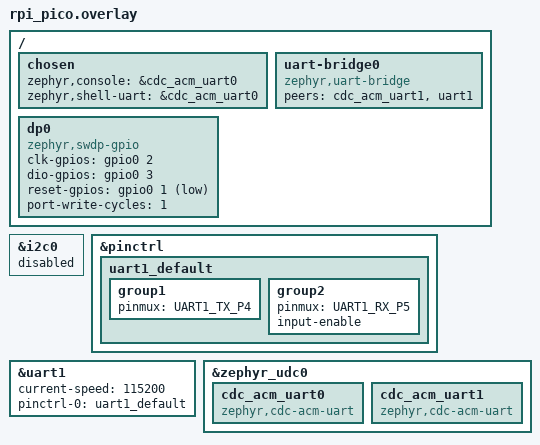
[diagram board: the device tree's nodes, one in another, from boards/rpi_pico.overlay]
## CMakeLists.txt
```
# SPDX-License-Identifier: Apache-2.0

cmake_minimum_required(VERSION 3.20.0)
find_package(Zephyr REQUIRED HINTS $ENV{ZEPHYR_BASE})
project(pico_probe)

FILE(GLOB app_sources src/*.c)
target_sources(app PRIVATE ${app_sources})
```

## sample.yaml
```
sample:
  name: Pico Probe CMSIS-DAP

tests:
  app.default:
    build_only: true
```

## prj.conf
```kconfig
# Enable USB device susbsytem
CONFIG_USB_DEVICE_STACK_NEXT=y

# CMSIS-DAP
CONFIG_DAP=y
CONFIG_DAP_BACKEND_USB=y

# Serial
CONFIG_SERIAL=y
CONFIG_UART_INTERRUPT_DRIVEN=y
CONFIG_UART_LINE_CTRL=y

# GPIO
CONFIG_GPIO=y

# Logs
CONFIG_LOG=y

# Don't auto-init CDC-ACM (we do it manually)
CONFIG_CDC_ACM_SERIAL_INITIALIZE_AT_BOOT=n
```

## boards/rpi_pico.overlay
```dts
/*
 * Copyright (c) 2025 Sam Kwort
 *
 * SPDX-License-Identifier: Apache-2.0
 *
 *
 * Pin mapping:
 *
 *   GP1  nRESET   Target reset (active low)
 *   GP2  SWCLK    SWD clock to target
 *   GP3  SWDIO    SWD data (bidirectional, pull-up)
 *   GP4  UART TX  UART1 TX -> target RX
 *   GP5  UART RX  UART1 RX <- target TX
 */

#include <dt-bindings/pinctrl/rpi-pico-rp2040-pinctrl.h>

/ {
	chosen {
		/* Route console/shell output over USB CDC-ACM instead of HW UART */
		zephyr,console = &cdc_acm_uart0;
		zephyr,shell-uart = &cdc_acm_uart0;
	};

	/*
	 * UART bridge: forwards bytes between USB CDC-ACM #1 and
	 * physical UART1 (GP4 TX, GP5 RX). The zephyr,uart-bridge
	 * driver handles this entirely -- no application code needed.
	 */
	uart-bridge0 {
		compatible = "zephyr,uart-bridge";
		peers = <&cdc_acm_uart1 &uart1>;
	};

	/*
	 * SWD debug port: bit-banged GPIO implementation of the
	 * CMSIS-DAP SWD interface. The DAP subsystem drives these
	 * pins to read/write target memory, set breakpoints, etc.
	 */
	dp0 {
		compatible = "zephyr,swdp-gpio";
		status = "okay";
		clk-gpios = <&gpio0 2 GPIO_ACTIVE_HIGH>;	/* GP2 = SWCLK */
		dio-gpios = <&gpio0 3 GPIO_PULL_UP>;		/* GP3 = SWDIO */
		reset-gpios = <&gpio0 1 GPIO_ACTIVE_LOW>;	/* GP1 = nRESET */
		port-write-cycles = <1>;
	};
};

/*
 * Disable i2c0 -- the default rpi_pico board maps it to GP4/GP5,
 * which conflicts with UART1. We don't need I2C on a debug probe.
 */
&i2c0 {
	status = "disabled";
};

/*
 * UART1 pinctrl: assign TX to GP4, RX to GP5.
 * Follows the pattern from the rpi_debug_probe board definition.
 */
&pinctrl {
	uart1_default: uart1_default {
		group1 {
			pinmux = <UART1_TX_P4>;
		};
		group2 {
			pinmux = <UART1_RX_P5>;
			input-enable;
		};
	};
};

/* Enable UART1 at 115200 baud for the UART bridge */
&uart1 {
	current-speed = <115200>;
	status = "okay";
	pinctrl-0 = <&uart1_default>;
	pinctrl-names = "default";
};

/* USB CDC-ACM instances under the USB device controller */
&zephyr_udc0 {
	/* CDC-ACM0: probe firmware console/logs */
	cdc_acm_uart0: cdc_acm_uart0 {
		compatible = "zephyr,cdc-acm-uart";
	};

	/* CDC-ACM1: UART bridge to target (paired with uart1 above) */
	cdc_acm_uart1: cdc_acm_uart1 {
		compatible = "zephyr,cdc-acm-uart";
	};
};
```

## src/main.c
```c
/*
 * Copyright (c) 2023 Nordic Semiconductor ASA
 *
 * SPDX-License-Identifier: Apache-2.0
 */

/*
 * Pico Probe main entry point.
 *
 * Brings up the three subsystems that make this a debug probe:
 *
 *   1. DAP controller  -- CMSIS-DAP command processor, backed by the
 *                         swdp-gpio driver that bit-bangs SWD on GP2/GP3
 *   2. USB device      -- composite device with CMSIS-DAP bulk interface
 *                         + two CDC-ACM serial ports (console & UART bridge)
 *   3. MS OS 2.0 BOS   -- tells Windows to bind WinUSB to the CMSIS-DAP
 *                         interface automatically (no manual driver install)
 *
 * The UART bridge (CDC-ACM <-> UART1) is handled entirely by the
 * "zephyr,uart-bridge" driver instantiated in the devicetree overlay --
 * no code needed here.
 */

#include <zephyr/kernel.h>
#include <zephyr/device.h>
#include <zephyr/usb/usbd.h>
#include <zephyr/usb/bos.h>
#include <zephyr/usb/msos_desc.h>
#include <zephyr/sys/byteorder.h>
#include <zephyr/logging/log.h>

#include <cmsis_dap.h>

/*
 * LOG_MODULE_REGISTER must come before msosv2.h because that header
 * uses LOG_INF in its static callback function. The LOG macros need
 * the log module context (__log_level, etc.) to be declared first.
 */
LOG_MODULE_REGISTER(pico_probe, LOG_LEVEL_INF);

#include "usb_init.h"
#include "msosv2.h"

int main(void)
{
    int ret;

    /*
     * Step 1: Get the SWD debug port device from devicetree.
     *
     * DEVICE_DT_GET_ONE finds the single instance of "zephyr,swdp-gpio"
     * defined in our board overlay (dp0 node). This device drives
     * SWCLK (GP2), SWDIO (GP3), and nRESET (GP6).
     */
    const struct device *const swd_dev = DEVICE_DT_GET_ONE(zephyr_swdp_gpio);

    /*
     * Step 2: Register the SWD device with the DAP subsystem.
     *
     * dap_setup() connects the CMSIS-DAP command processor to our
     * SWD GPIO driver. After this, incoming USB DAP commands will
     * be translated into SWD bus transactions on the physical pins.
     */
    ret = dap_setup(swd_dev);
    if (ret) {
        LOG_ERR("Failed to initialise DAP controller (%d)", ret);
        return ret;
    }

    /*
     * Step 3: Build the USB device context.
     *
     * usb_setup_device() (in usb_init.c) creates the device context
     * with our VID/PID, string descriptors, a Full-Speed configuration,
     * and registers all USB class instances (CMSIS-DAP + 2x CDC-ACM).
     *
     * It returns *without* calling usbd_init/usbd_enable so we can
     * add BOS descriptors first (next step).
     */
    struct usbd_context *usbd = usb_setup_device();
    if (usbd == NULL) {
        LOG_ERR("Failed to set up USB device");
        return -ENODEV;
    }

    /*
     * Step 4: Add the MS OS 2.0 BOS capability descriptor.
     *
     * This is a Binary Object Store (BOS) descriptor that Windows
     * reads during enumeration. It contains:
     *   - A WINUSB compatible ID so Windows loads its generic USB driver
     *   - The CMSIS-DAP v2 device interface GUID so debug tools can
     *     find the device
     *
     * Without this, Windows would require manual driver installation.
     */
    ret = usbd_add_descriptor(usbd, &bos_vreq_msosv2);
    if (ret) {
        LOG_ERR("Failed to add MS OS 2.0 capability descriptor (%d)", ret);
        return ret;
    }

    /*
     * Step 5: Initialise the USB device stack.
     *
     * usbd_init() validates the configuration and prepares the USB
     * controller hardware. After this call, the device descriptor
     * tree is frozen -- no more changes allowed.
     */
    ret = usbd_init(usbd);
    if (ret) {
        LOG_ERR("Failed to initialise USB device (%d)", ret);
        return ret;
    }

    /*
     * Step 6: Enable the USB device.
     *
     * usbd_enable() connects D+/D- pull-up, making the device visible
     * on the bus. The host will enumerate it and bind drivers to each
     * interface (CMSIS-DAP, CDC-ACM console, CDC-ACM UART bridge).
     */
    ret = usbd_enable(usbd);
    if (ret) {
        LOG_ERR("Failed to enable USB device (%d)", ret);
        return ret;
    }

    LOG_INF("Pico Probe ready");

    return 0;
}
```

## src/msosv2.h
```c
/*
 * Copyright (c) 2016-2019 Intel Corporation
 * Copyright (c) 2023-2024 Nordic Semiconductor ASA
 *
 * SPDX-License-Identifier: Apache-2.0
 */

#ifndef ZEPHYR_INCLUDE_MSOSV2_DESCRIPTOR_H
#define ZEPHYR_INCLUDE_MSOSV2_DESCRIPTOR_H

/*
 * Microsoft OS 2.0 platform capability and Microsoft OS 2.0 descriptor set.
 * See Microsoft OS 2.0 Descriptors Specification for reference.
 */

#define PROBE_MSOS2_VENDOR_CODE		0x02U
/* Windows version (10) */
#define PROBE_MSOS2_OS_VERSION		0x0A000000UL

/* {CDB3B5AD-293B-4663-AA36-1AAE46463776} */
#define CMSIS_DAP_V2_DEVICE_INTERFACE_GUID \
	'{', 0x00, 'C', 0x00, 'D', 0x00, 'B', 0x00, '3', 0x00, 'B', 0x00, \
	'5', 0x00, 'A', 0x00, 'D', 0x00, '-', 0x00, '2', 0x00, '9', 0x00, \
	'3', 0x00, 'B', 0x00, '-', 0x00, '4', 0x00, '6', 0x00, '6', 0x00, \
	'3', 0x00, '-', 0x00, 'A', 0x00, 'A', 0x00, '3', 0x00, '6', 0x00, \
	'-', 0x00, '1', 0x00, 'A', 0x00, 'A', 0x00, 'E', 0x00, '4', 0x00, \
	'6', 0x00, '4', 0x00, '6', 0x00, '3', 0x00, '7', 0x00, '7', 0x00, \
	'6', 0x00, '}', 0x00, 0x00, 0x00, 0x00, 0x00

#define CDC_ACM_DESCRIPTOR_LENGTH 160

struct msosv2_descriptor {
	struct msosv2_descriptor_set_header header;
#if defined(CONFIG_USBD_CDC_ACM_CLASS)
	/*
	 * The composition of this descriptor is specific to the WebUSB example
	 * in its default configuration. If you use it for your application or
	 * change the configuration, you may need to modify this descriptor for
	 * your USB device. The following only covers the case where the CDC
	 * ACM implementation is enabled, and there is only one CDC ACM UART
	 * instance, and the CDC ACM communication interface is the first in
	 * the configuration.
	 */
	struct msosv2_function_subset_header subset_header;
#endif
	struct msosv2_compatible_id compatible_id;
	struct msosv2_guids_property guids_property;
} __packed;

static struct msosv2_descriptor msosv2_desc = {
	.header = {
		.wLength = sizeof(struct msosv2_descriptor_set_header),
		.wDescriptorType = MS_OS_20_SET_HEADER_DESCRIPTOR,
		.dwWindowsVersion = sys_cpu_to_le32(PROBE_MSOS2_OS_VERSION),
		.wTotalLength = sizeof(msosv2_desc),
	},
#if defined(CONFIG_USBD_CDC_ACM_CLASS)
	.subset_header = {
		.wLength = sizeof(struct msosv2_function_subset_header),
		.wDescriptorType = MS_OS_20_SUBSET_HEADER_FUNCTION,
		.bFirstInterface = 0,
		.wSubsetLength = CDC_ACM_DESCRIPTOR_LENGTH,
	},
#endif
	.compatible_id = {
		.wLength = sizeof(struct msosv2_compatible_id),
		.wDescriptorType = MS_OS_20_FEATURE_COMPATIBLE_ID,
		.CompatibleID = {'W', 'I', 'N', 'U', 'S', 'B', 0x00, 0x00},
	},
	.guids_property = {
		.wLength = sizeof(struct msosv2_guids_property),
		.wDescriptorType = MS_OS_20_FEATURE_REG_PROPERTY,
		.wPropertyDataType = MS_OS_20_PROPERTY_DATA_REG_MULTI_SZ,
		.wPropertyNameLength = 42,
		.PropertyName = {DEVICE_INTERFACE_GUIDS_PROPERTY_NAME},
		.wPropertyDataLength = 80,
		.bPropertyData = {CMSIS_DAP_V2_DEVICE_INTERFACE_GUID},
	},
};

struct bos_msosv2_descriptor {
	struct usb_bos_platform_descriptor platform;
	struct usb_bos_capability_msos cap;
} __packed;

struct bos_msosv2_descriptor bos_msosv2_desc = {
	/*
	 * Microsoft OS 2.0 Platform Capability Descriptor,
	 * see Microsoft OS 2.0 Descriptors Specification
	 */
	.platform = {
		.bLength = sizeof(struct usb_bos_platform_descriptor)
			 + sizeof(struct usb_bos_capability_msos),
		.bDescriptorType = USB_DESC_DEVICE_CAPABILITY,
		.bDevCapabilityType = USB_BOS_CAPABILITY_PLATFORM,
		.bReserved = 0,
		/* Microsoft OS 2.0 descriptor platform capability UUID
		 * D8DD60DF-4589-4CC7-9CD2-659D9E648A9F
		 */
		.PlatformCapabilityUUID = {
			0xDF, 0x60, 0xDD, 0xD8,
			0x89, 0x45,
			0xC7, 0x4C,
			0x9C, 0xD2,
			0x65, 0x9D, 0x9E, 0x64, 0x8A, 0x9F,
		},
	},
	.cap = {
		.dwWindowsVersion = sys_cpu_to_le32(PROBE_MSOS2_OS_VERSION),
		.wMSOSDescriptorSetTotalLength = sys_cpu_to_le16(sizeof(msosv2_desc)),
		.bMS_VendorCode = PROBE_MSOS2_VENDOR_CODE,
		.bAltEnumCode = 0x00
	},
};

static int msosv2_to_host_cb(const struct usbd_context *const ctx,
			     const struct usb_setup_packet *const setup,
			     struct net_buf *const buf)
{
	LOG_INF("Vendor callback to host");

	if (setup->bRequest == PROBE_MSOS2_VENDOR_CODE &&
	    setup->wIndex == MS_OS_20_DESCRIPTOR_INDEX) {
		LOG_INF("Get MS OS 2.0 Descriptor Set");

		net_buf_add_mem(buf, &msosv2_desc,
				MIN(net_buf_tailroom(buf), sizeof(msosv2_desc)));

		return 0;
	}

	return -ENOTSUP;
}

USBD_DESC_BOS_VREQ_DEFINE(bos_vreq_msosv2, sizeof(bos_msosv2_desc), &bos_msosv2_desc,
			  PROBE_MSOS2_VENDOR_CODE, msosv2_to_host_cb, NULL);

#endif /* ZEPHYR_INCLUDE_MSOSV2_DESCRIPTOR_H */
```

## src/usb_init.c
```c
/*
 * Copyright (c) 2023 Nordic Semiconductor ASA
 *
 * SPDX-License-Identifier: Apache-2.0
 */

/*
 * USB device setup for the Pico Probe.
 *
 * Derived from zephyr/samples/subsys/usb/common/sample_usbd_init.c with
 * Kconfig references replaced by #define constants.
 *
 * This file builds a USB "device context" -- Zephyr's representation of the
 * entire USB device -- and populates it with:
 *
 *   1. Identity descriptors  (VID, PID, manufacturer/product strings)
 *   2. A configuration       (Full-Speed only; RP2040 has no High-Speed)
 *   3. All USB class instances registered in devicetree / Kconfig
 *      (CMSIS-DAP bulk interface, two CDC-ACM serial ports)
 *   4. The device-descriptor "code triple" required by the USB spec when
 *      Interface Association Descriptors (IAD) are present
 *
 * The caller (main.c) then adds BOS capability descriptors (e.g. MS OS 2.0)
 * and calls usbd_init() + usbd_enable() to go live on the bus.
 */

#include <stdint.h>

#include <zephyr/device.h>
#include <zephyr/usb/usbd.h>
#include <zephyr/usb/bos.h>
#include <zephyr/logging/log.h>

#include "usb_init.h"

LOG_MODULE_REGISTER(probe_usb);

/* USB identity -- VID 0x2fe3 is the Zephyr Project vendor ID (dev use only) */
#define PROBE_USB_VID          0x2fe3
#define PROBE_USB_PID          0x0204
#define PROBE_USB_MANUFACTURER "Zephyr Project"
#define PROBE_USB_PRODUCT      "Pico Probe CMSIS-DAP"
#define PROBE_USB_MAX_POWER    250 /* mA */

/* Block DFU mode instance if present */
static const char *const blocklist[] = {
    "dfu_dfu",
    NULL,
};

/*
 * --- Static USB object declarations (compile-time) ---
 *
 * Zephyr's USB device stack uses macros to declare USB objects at compile
 * time. These end up in special linker sections so the stack can find them.
 */

/* The top-level USB device context -- ties everything together */
USBD_DEVICE_DEFINE(probe_usbd, DEVICE_DT_GET(DT_NODELABEL(zephyr_udc0)),
                   PROBE_USB_VID, PROBE_USB_PID);

/* Standard string descriptors that the host reads during enumeration */
USBD_DESC_LANG_DEFINE(probe_lang);
USBD_DESC_MANUFACTURER_DEFINE(probe_mfr, PROBE_USB_MANUFACTURER);
USBD_DESC_PRODUCT_DEFINE(probe_product, PROBE_USB_PRODUCT);

/* Human-readable label for the configuration (visible in USB analysers) */
USBD_DESC_CONFIG_DEFINE(fs_cfg_desc, "FS Configuration");

/* Full-Speed configuration descriptor (RP2040 is Full-Speed only, 12 Mbit/s) */
USBD_CONFIGURATION_DEFINE(probe_fs_config, 0, PROBE_USB_MAX_POWER,
                          &fs_cfg_desc);

/*
 * Set the USB device descriptor "code triple":
 *   bDeviceClass / bDeviceSubClass / bDeviceProtocol
 *
 * These three bytes in the device descriptor tell the host what kind of
 * device this is *before* it looks at individual interfaces.
 *
 * - Simple device (one function): set all to 0 -- means "check my
 *   interface descriptors to find out what I do."
 *
 * - Composite device with CDC-ACM (like ours): the CDC-ACM class uses
 *   two USB interfaces per port (communication + data), grouped by an
 *   Interface Association Descriptor (IAD). The USB spec requires that
 *   any device using IADs advertise this specific triple:
 *
 *       bDeviceClass    = 0xEF  (Miscellaneous)
 *       bDeviceSubClass = 0x02  (Common Class)
 *       bDeviceProtocol = 0x01  (Interface Association)
 *
 *   Without this, Windows will fail to bind the CDC-ACM interfaces.
 */
static void probe_fix_code_triple(struct usbd_context *uds_ctx)
{
    if (IS_ENABLED(CONFIG_USBD_CDC_ACM_CLASS)) {
        usbd_device_set_code_triple(uds_ctx, USBD_SPEED_FS,
                                    USB_BCC_MISCELLANEOUS, 0x02, 0x01);
    } else {
        usbd_device_set_code_triple(uds_ctx, USBD_SPEED_FS, 0, 0, 0);
    }
}

/*
 * Build the USB device context at runtime.
 *
 * Returns a pointer to the context on success (caller then calls
 * usbd_init + usbd_enable), or NULL on failure.
 */
struct usbd_context *usb_setup_device(void)
{
    int err;

    /*
     * Step 1: Register string descriptors.
     *
     * These are the human-readable strings the host displays when you
     * plug the device in (e.g. "Pico Probe CMSIS-DAP" in Device Manager).
     */
    err = usbd_add_descriptor(&probe_usbd, &probe_lang);
    if (err) {
        LOG_ERR("Failed to add language descriptor (%d)", err);
        return NULL;
    }

    err = usbd_add_descriptor(&probe_usbd, &probe_mfr);
    if (err) {
        LOG_ERR("Failed to add manufacturer descriptor (%d)", err);
        return NULL;
    }

    err = usbd_add_descriptor(&probe_usbd, &probe_product);
    if (err) {
        LOG_ERR("Failed to add product descriptor (%d)", err);
        return NULL;
    }

    /*
     * Step 2: Add a USB configuration.
     *
     * A USB device can have multiple configurations (e.g. low-power vs
     * high-power), but almost all devices have exactly one. The host
     * selects it during enumeration with SET_CONFIGURATION.
     */
    err = usbd_add_configuration(&probe_usbd, USBD_SPEED_FS, &probe_fs_config);
    if (err) {
        LOG_ERR("Failed to add Full-Speed configuration");
        return NULL;
    }

    /*
     * Step 3: Register all USB class instances.
     *
     * This walks every USB class enabled in Kconfig / devicetree and
     * attaches it to our configuration. For this probe that means:
     *   - CMSIS-DAP bulk interface  (from CONFIG_DAP_BACKEND_USB)
     *   - CDC-ACM uart0             (console logs)
     *   - CDC-ACM uart1             (UART bridge)
     *
     * The blocklist excludes classes we don't want (e.g. DFU mode).
     */
    err = usbd_register_all_classes(&probe_usbd, USBD_SPEED_FS, 1, blocklist);
    if (err) {
        LOG_ERR("Failed to register classes");
        return NULL;
    }

    /*
     * Step 4: Fix up the device descriptor code triple.
     *
     * Must happen after classes are registered so we know whether
     * CDC-ACM (and therefore IADs) are in use.
     */
    probe_fix_code_triple(&probe_usbd);

    return &probe_usbd;
}
```

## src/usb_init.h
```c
/*
 * Copyright (c) 2023 Nordic Semiconductor ASA
 *
 * SPDX-License-Identifier: Apache-2.0
 */

#ifndef PROBE_USB_INIT_H
#define PROBE_USB_INIT_H

#include <zephyr/usb/usbd.h>

/*
 * Set up and return the USB device context for the probe.
 * Configures descriptors, registers classes, but does NOT
 * call usbd_init() or usbd_enable() - caller does that
 * after adding BOS descriptors.
 */
struct usbd_context *usb_setup_device(void);

#endif /* PROBE_USB_INIT_H */
```
